# AVR16DU32 register map
Vendor: Atmel; File version: 1.0
CPU: other r0p0, little endian, no MPU, no FPU, 4 interrupt priority bits
Registers are 8-bit, read-write, reset 0x0 unless marked. A register's access mark holds for its fields unless they carry their own. Offsets are from the block's base; [hi:lo] are bit positions; {n}, {i} and the like mark numbered series.

## ADC0 — Analog to Digital Converter
Base 0x00800600
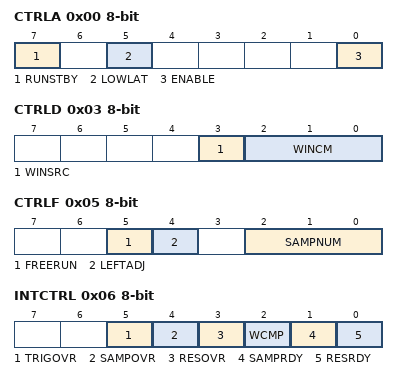
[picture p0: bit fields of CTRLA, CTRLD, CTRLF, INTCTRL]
0x00 CTRLA — Control A
  [7] RUNSTBY — Run standby mode
  [5] LOWLAT — Conversion mode
  [0] ENABLE — ADC Enable
0x01 CTRLB — Control C
  [3:0] PRESC — Clock Pre-scaler
    0=DIV2 (CLK_PER divided by 2); 1=DIV4 (CLK_PER divided by 4); 2=DIV6 (CLK_PER divided by 6); 3=DIV8 (CLK_PER divided by 8); 4=DIV10 (CLK_PER divided by 10); 5=DIV12 (CLK_PER divided by 12); 6=DIV14 (CLK_PER divided by 14); 7=DIV16 (CLK_PER divided by 16); 8=DIV20 (CLK_PER divided by 20); 9=DIV24 (CLK_PER divided by 24); 10=DIV28 (CLK_PER divided by 28); 11=DIV32 (CLK_PER divided by 32); 12=DIV40 (CLK_PER divided by 40); 13=DIV48 (CLK_PER divided by 48); 14=DIV56 (CLK_PER divided by 56); 15=DIV64 (CLK_PER divided by 64)
0x02 CTRLC — Control B
  [2:0] REFSEL — Reference Selection
    0=VDD; 2=VREFA; 4=1V024 (1.024V); 5=2V048 (2.048V); 6=4V096 (4.096V); 7=2V500 (2.5V)
0x03 CTRLD — Control E
  [3] WINSRC — Window Mode Source
  [2:0] WINCM — Window Comparator Mode
    0=NONE (No Window Comparison); 1=BELOW (Below Window); 2=ABOVE (Above Window); 3=INSIDE (Inside Window); 4=OUTSIDE (Outside Window)
0x04 CTRLE — Control F
  [7:0] SAMPDUR — Sample Duration
0x05 CTRLF — Control D
  [5] FREERUN — Free Running
  [4] LEFTADJ — Left Adjust
  [2:0] SAMPNUM — Sampling Number
    0=NONE (No accumulation); 1=ACC2 (2 results accumulated); 2=ACC4 (4 results accumulated); 3=ACC8 (8 results accumulated); 4=ACC16 (16 results accumulated); 5=ACC32 (32 results accumulated); 6=ACC64 (64 results accumulated)
0x06 INTCTRL — Interrupt Control
  [5] TRIGOVR — Trigger Overrun Interrupt Enable
  [4] SAMPOVR — Sample Overwrite Interrupt Enable
  [3] RESOVR — Result Overwrite Interrupt Enable
  [2] WCMP — Window Comparator Interrupt Enable
  [1] SAMPRDY — Sample Ready Interrupt Enable
  [0] RESRDY — Result Ready Interrupt Enable
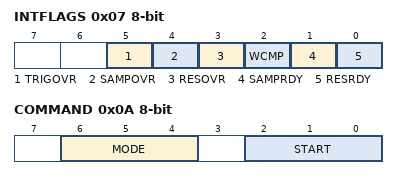
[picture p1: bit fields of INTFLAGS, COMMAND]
0x07 INTFLAGS — Interrupt Flags
  [5] TRIGOVR — Trigger OverrunFlag
  [4] SAMPOVR — Sample OverwriteFlag
  [3] RESOVR — Result OverwriteFlag
  [2] WCMP — Window Comparator Flag
  [1] SAMPRDY — Sample Ready Flag
  [0] RESRDY — Result Ready Flag
0x08 STATUS ro
  [0] ADCBUSY
0x09 DBGCTRL — Debug Control
  [0] DBGRUN — Debug run
0x0A COMMAND
  [6:4] MODE
    0=SINGLE_8BIT (Single 8-bit conv); 1=SINGLE_10BIT (Single 10-bit conv); 2=SERIES (Series of 10-bit conv); 3=BURST (Burst of 10-bit conv); 7=ACCTEST (Acc test mode for FuSa)
  [2:0] START — Start Conversion
    0=STOP (Stop/No ongoing conv); 1=IMMEDIATE (Start Immediately); 2=MUXPOS_WRITE (Start after a write to MUXPOS); 4=EVENT_TRIGGER (Start upon event reception)
0x0B MUXPOS — Positive mux input
  [6:0] MUXPOS — Analog Channel Selection Bits
    {v}=AIN{v} (ADC input pin {v}) (v=0..7); {v}=AIN{v} (ADC input pin {v}) (v=16..27); 31=AIN31 (ADC input pin 31); 64=GND (Ground); 66=TEMPSENSE (Temperature sensor); 68=VDDDIV10 (VDD/10); 73=DACREF0 (AC0 DAC voltage)
0x0C RESULT 16-bit ro (reset mask 0xFF) — ADC Accumulator Result
  [15:0] RESULT — ADC Result
0x0E SAMPLE 16-bit (reset mask 0xFF) — ADC Sample
  [15:0] SAMPLE ro
0x10 WINLT 16-bit (reset mask 0xFF) — Window comparator low threshold
  [15:0] WINLT — Window Low Threshold
0x12 WINHT 16-bit (reset mask 0xFF) — Window comparator high threshold
  [15:0] WINHT — Window High Threshold
0x14 TEMP — Temporary Data
  [7:0] TEMP — Temporary

## BOD — Bod interface
Base 0x008000A0
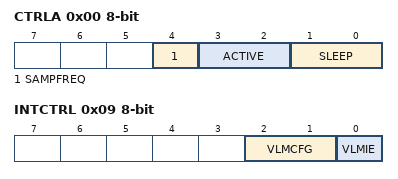
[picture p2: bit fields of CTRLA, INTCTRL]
0x00 CTRLA — Control A
  [4] SAMPFREQ ro — Sample frequency
    0=128HZ (128Hz sampling frequency); 1=32HZ (32Hz sampling frequency)
  [3:2] ACTIVE ro — Operation in active mode
    0=DIS (Disabled); 1=ENABLED; 2=SAMPLED; 3=ENWAKE (Enabled with wake-up halted until BOD is ready)
  [1:0] SLEEP — Operation in sleep mode
    0=DIS (Disabled); 1=ENABLED; 2=SAMPLED
0x01 CTRLB — Control B
  [2:0] LVL ro — Bod level
    0=BODLEVEL0 (1.9 V); 1=BODLEVEL1 (2.45 V); 2=BODLEVEL2 (2.7 V); 3=BODLEVEL3 (2.85 V)
0x08 VLMCTRLA — Voltage level monitor Control
  [1:0] VLMLVL — voltage level monitor level
    0=OFF (VLM Disabled); 1=5ABOVE (VLM threshold 5% above BOD level); 2=15ABOVE (VLM threshold 15% above BOD level); 3=25ABOVE (VLM threshold 25% above BOD level)
0x09 INTCTRL — Voltage level monitor interrupt Control
  [2:1] VLMCFG — Configuration
    0=FALLING (VDD falls below VLM threshold); 1=RISING (VDD rises above VLM threshold); 2=BOTH (VDD crosses VLM threshold)
  [0] VLMIE — voltage level monitor interrrupt enable
0x0A INTFLAGS — Voltage level monitor interrupt Flags
  [0] VLMIF — Voltage level monitor interrupt flag
0x0B STATUS — Voltage level monitor status
  [0] VLMS ro
    0=ABOVE (The voltage is above the VLM threshold level); 1=BELOW (The voltage is below the VLM threshold level)
